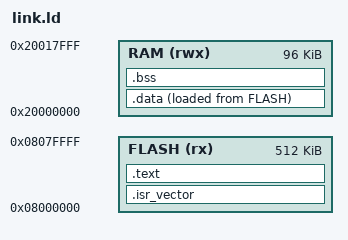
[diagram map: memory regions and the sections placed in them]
MEMORY
{
  FLASH (rx)  : ORIGIN = 0x08000000, LENGTH = 512K
  RAM   (rwx) : ORIGIN = 0x20000000, LENGTH = 96K
}
_estack = ORIGIN(RAM) + LENGTH(RAM);
ENTRY(reset_handler)
SECTIONS
{
  .isr_vector : { KEEP(*(.isr_vector)) } > FLASH
  .text : { *(.text*) *(.rodata*) . = ALIGN(4); } > FLASH
  _sidata = LOADADDR(.data);
  .data : { _sdata = .; *(.data*) . = ALIGN(4); _edata = .; } > RAM AT > FLASH
  .bss (NOLOAD) : { _sbss = .; *(.bss*) *(COMMON) . = ALIGN(4); _ebss = .; } > RAM
  /DISCARD/ : { *(.ARM.exidx*) *(.ARM.attributes) *(.comment) }
}
